# FIXTURE register map
File version: 1
Registers are read-write, no defined reset value unless marked. A register's access mark holds for its fields unless they carry their own. Offsets are from the block's base; lines under a group give offsets from that group; [hi:lo] are bit positions; {n}, {i} and the like mark numbered series; 'fields as' and 'values as' point back to an identical list; <NAME> marks a mode.

## Memory map
0x00000000 FIXTURE size 0x1000

## FIXTURE
Base 0x00000000
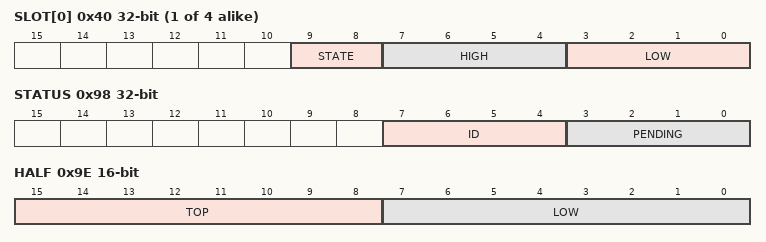
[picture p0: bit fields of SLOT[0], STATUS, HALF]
{0x40+8i} SLOT[{i}] (i=0..3)
  [9:8] STATE ro, [7:4] HIGH, [3:0] LOW
0x80 RING_BASE 64-bit
  [63:0] ADDRESS
0x88 WIDE 64-bit
  [63:0] ALL
0x90 DOORBELL wo
  [7:0] QUEUE
0x94 POP read-clears
  [7:0] VALUE
0x98 STATUS
  [7:4] ID ro, [3:0] PENDING write-1-clears
0x9C PICK 8-bit
  [7:0] VALUE
0x9D COUNT 8-bit ro
  [7:0] VALUE
0x9E HALF 16-bit
  [15:8] TOP, [7:0] LOW

## Notices in the file
Copyright (c) 2026, Stanislav Sedov <stas@deglitch.com>
SPDX-License-Identifier: BSD-2-Clause
